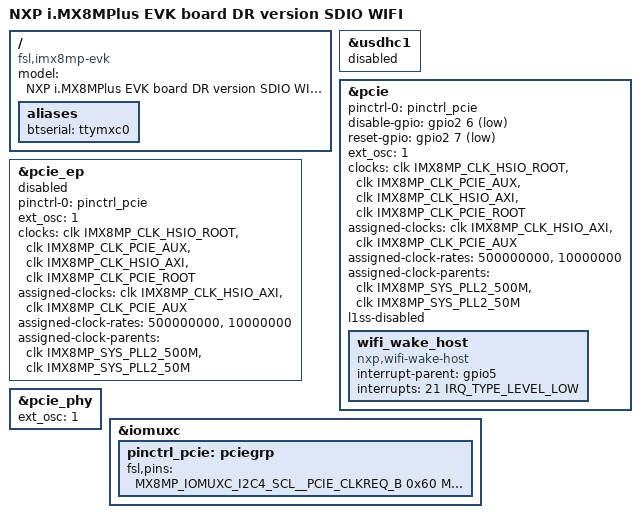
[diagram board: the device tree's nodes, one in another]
// SPDX-License-Identifier: (GPL-2.0+ OR MIT)
/*
 * Copyright 2019 NXP
 */

/dts-v1/;

#include "dr-imx8mp-evk.dtsi"

/ {
	model = "NXP i.MX8MPlus EVK board DR version SDIO WIFI";
	compatible = "fsl,imx8mp-evk", "fsl,imx8mp";

	aliases {
		btserial = "ttymxc0";
	};
};

&usdhc1 {
	status = "disabled";
};


&pcie{
	pinctrl-names = "default";
	pinctrl-0 = <&pinctrl_pcie>;
	disable-gpio = <&gpio2 6 GPIO_ACTIVE_LOW>;
	reset-gpio = <&gpio2 7 GPIO_ACTIVE_LOW>;
	ext_osc = <1>;
	clocks = <&clk IMX8MP_CLK_HSIO_ROOT>,
		 <&clk IMX8MP_CLK_PCIE_AUX>,
		 <&clk IMX8MP_CLK_HSIO_AXI>,
		 <&clk IMX8MP_CLK_PCIE_ROOT>;
	clock-names = "pcie", "pcie_aux", "pcie_phy", "pcie_bus";
	assigned-clocks = <&clk IMX8MP_CLK_HSIO_AXI>,
			  <&clk IMX8MP_CLK_PCIE_AUX>;
	assigned-clock-rates = <500000000>, <10000000>;
	assigned-clock-parents = <&clk IMX8MP_SYS_PLL2_500M>,
				 <&clk IMX8MP_SYS_PLL2_50M>;
	l1ss-disabled;
	status = "okay";

	wifi_wake_host {
		compatible = "nxp,wifi-wake-host";
		interrupt-parent = <&gpio5>;
		interrupts = <21 IRQ_TYPE_LEVEL_LOW>;
		interrupt-names = "host-wake";
	};
};

&pcie_ep{
	pinctrl-names = "default";
	pinctrl-0 = <&pinctrl_pcie>;
	ext_osc = <1>;
	clocks = <&clk IMX8MP_CLK_HSIO_ROOT>,
		 <&clk IMX8MP_CLK_PCIE_AUX>,
		 <&clk IMX8MP_CLK_HSIO_AXI>,
		 <&clk IMX8MP_CLK_PCIE_ROOT>;
	clock-names = "pcie", "pcie_aux", "pcie_phy", "pcie_bus";
	assigned-clocks = <&clk IMX8MP_CLK_HSIO_AXI>,
			  <&clk IMX8MP_CLK_PCIE_AUX>;
	assigned-clock-rates = <500000000>, <10000000>;
	assigned-clock-parents = <&clk IMX8MP_SYS_PLL2_500M>,
				 <&clk IMX8MP_SYS_PLL2_50M>;
	status = "disabled";
};

&pcie_phy{
	ext_osc = <1>;
	status = "okay";
};

&iomuxc {
	pinctrl_pcie: pciegrp {
		fsl,pins = <
			MX8MP_IOMUXC_I2C4_SCL__PCIE_CLKREQ_B	0x60 /* open drain, pull up */
			MX8MP_IOMUXC_SD1_DATA4__GPIO2_IO06		0x40
			MX8MP_IOMUXC_SD1_DATA5__GPIO2_IO07		0x40
			MX8MP_IOMUXC_I2C4_SDA__GPIO5_IO21		0x1c4
		>;
	};
};
